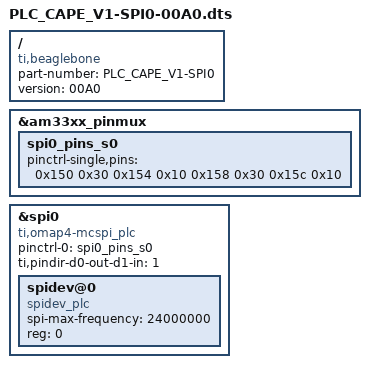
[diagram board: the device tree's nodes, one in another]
/dts-v1/;
/plugin/;
 
/ {
    compatible = "ti,beaglebone", "ti,beaglebone-black";
 
    /* identification */
    part-number = "PLC_CAPE_V1-SPI0";
 
    /* version */
    version = "00A0";
 
    fragment@0 {
        target = <&am33xx_pinmux>;
        __overlay__ {
            spi0_pins_s0: spi0_pins_s0 {
                pinctrl-single,pins = <
                  0x150 0x30 /* spi0_sclk, INPUT_PULLUP | MODE0 */
                  /* D0 & D1 toggled with regards to std configuration */
                  0x154 0x10 /* spi0_d0, OUTPUT_PULLUP | MODE0 */ 
                  0x158 0x30 /* spi0_d1, INPUT_PULLUP | MODE0 */
                  0x15c 0x10 /* spi0_cs0, OUTPUT_PULLUP | MODE0 */
                >;
            };
        };
    };

    fragment12 {
        target = <&spi0>;
        __overlay__ {
             /* Std definition hook for redirection to patched drivers */
             compatible = "ti,omap4-mcspi_plc";
             #address-cells = <1>;
             #size-cells = <0>;

             status = "okay";
             pinctrl-names = "default";
             pinctrl-0 = <&spi0_pins_s0>;
             /* D0 & D1 toggled with regards to std configuration*/
             ti,pindir-d0-out-d1-in = <1>;
             
             spidev@0 {
                 spi-max-frequency = <24000000>;
                 reg = <0>;
                 compatible = "spidev_plc";
             };
        };
    };

};
